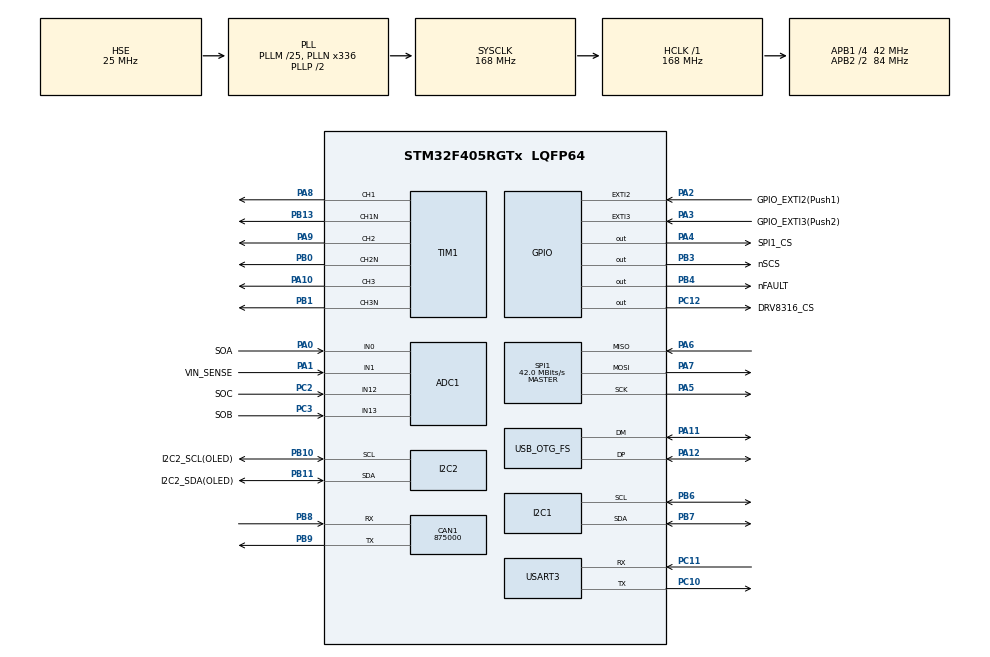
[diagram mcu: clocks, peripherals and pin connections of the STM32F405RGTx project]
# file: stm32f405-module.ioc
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ADC1.Channel-1\#ChannelRegularConversion=ADC_CHANNEL_0
ADC1.NbrOfConversionFlag=1
ADC1.Rank-1\#ChannelRegularConversion=1
ADC1.SamplingTime-1\#ChannelRegularConversion=ADC_SAMPLETIME_3CYCLES
ADC1.master=1
CAN1.BS1=CAN_BS1_1TQ
CAN1.BS2=CAN_BS2_1TQ
CAN1.CalculateBaudRate=875000
CAN1.CalculateTimeBit=1142
CAN1.CalculateTimeQuantum=380.95238095238096
Mcu.Family=STM32F4
Mcu.Name=STM32F405RGTx
Mcu.Package=LQFP64
NVIC.OTG_FS_IRQn=true\:0\:0\:false\:false\:true\:false\:true\:true
NVIC.PriorityGroup=NVIC_PRIORITYGROUP_4
PA0-WKUP.GPIO_Label=SOA
PA0-WKUP.Signal=ADCx_IN0
PA1.GPIO_Label=VIN_SENSE
PA1.Signal=ADCx_IN1
PA10.Signal=S_TIM1_CH3
PA11.Mode=Device_Only
PA11.Signal=USB_OTG_FS_DM
PA12.Mode=Device_Only
PA12.Signal=USB_OTG_FS_DP
PA13.Mode=Serial_Wire
PA13.Signal=SYS_JTMS-SWDIO
PA14.Mode=Serial_Wire
PA14.Signal=SYS_JTCK-SWCLK
PA2.GPIO_Label=GPIO_EXTI2(Push1)
PA2.Signal=GPXTI2
PA3.GPIO_Label=GPIO_EXTI3(Push2)
PA3.Signal=GPXTI3
PA4.GPIO_Label=SPI1_CS
PA4.Signal=GPIO_Output
PA5.Mode=Full_Duplex_Master
PA5.Signal=SPI1_SCK
PA6.Mode=Full_Duplex_Master
PA6.Signal=SPI1_MISO
PA7.Mode=Full_Duplex_Master
PA7.Signal=SPI1_MOSI
PA8.Signal=S_TIM1_CH1
PA9.Signal=S_TIM1_CH2
PB0.Mode=PWM Generation2 CH2 CH2N
PB0.Signal=TIM1_CH2N
PB1.Mode=PWM Generation3 CH3 CH3N
PB1.Signal=TIM1_CH3N
PB10.GPIO_Label=I2C2_SCL(OLED)
PB10.Mode=I2C
PB10.Signal=I2C2_SCL
PB11.GPIO_Label=I2C2_SDA(OLED)
PB11.Mode=I2C
PB11.Signal=I2C2_SDA
PB13.Mode=PWM Generation1 CH1 CH1N
PB13.Signal=TIM1_CH1N
PB3.GPIO_Label=nSCS
PB3.Signal=GPIO_Output
PB4.GPIO_Label=nFAULT
PB4.Signal=GPIO_Output
PB6.Mode=I2C
PB6.Signal=I2C1_SCL
PB7.Mode=I2C
PB7.Signal=I2C1_SDA
PB8.Mode=CAN_Activate
PB8.Signal=CAN1_RX
PB9.Mode=CAN_Activate
PB9.Signal=CAN1_TX
PC10.Mode=Asynchronous
PC10.Signal=USART3_TX
PC11.Mode=Asynchronous
PC11.Signal=USART3_RX
PC12.GPIO_Label=DRV8316_CS
PC12.Signal=GPIO_Output
PC2.GPIO_Label=SOC
PC2.Signal=ADCx_IN12
PC3.GPIO_Label=SOB
PC3.Signal=ADCx_IN13
PH0-OSC_IN.Mode=HSE-External-Oscillator
PH0-OSC_IN.Signal=RCC_OSC_IN
PH1-OSC_OUT.Mode=HSE-External-Oscillator
PH1-OSC_OUT.Signal=RCC_OSC_OUT
ProjectManager.HeapSize=0x200
ProjectManager.StackSize=0x400
ProjectManager.TargetToolchain=CMake
RCC.48MHZClocksFreq_Value=48000000
RCC.AHBFreq_Value=168000000
RCC.APB1CLKDivider=RCC_HCLK_DIV4
RCC.APB1Freq_Value=42000000
RCC.APB1TimFreq_Value=84000000
RCC.APB2CLKDivider=RCC_HCLK_DIV2
RCC.APB2Freq_Value=84000000
RCC.APB2TimFreq_Value=168000000
RCC.CortexFreq_Value=168000000
RCC.HCLKFreq_Value=168000000
RCC.HSE_VALUE=25000000
RCC.HSI_VALUE=16000000
RCC.LSE_VALUE=32768
RCC.PLLM=25
RCC.PLLN=336
RCC.PLLQ=7
RCC.SYSCLKFreq_VALUE=168000000
RCC.SYSCLKSource=RCC_SYSCLKSOURCE_PLLCLK
RCC.VCOOutputFreq_Value=336000000
SH.ADCx_IN0.0=ADC1_IN0,IN0
SH.ADCx_IN1.0=ADC1_IN1,IN1
SH.ADCx_IN12.0=ADC1_IN12,IN12
SH.ADCx_IN13.0=ADC1_IN13,IN13
SH.S_TIM1_CH1.0=TIM1_CH1,PWM Generation1 CH1 CH1N
SH.S_TIM1_CH2.0=TIM1_CH2,PWM Generation2 CH2 CH2N
SH.S_TIM1_CH3.0=TIM1_CH3,PWM Generation3 CH3 CH3N
SPI1.CalculateBaudRate=42.0 MBits/s
SPI1.Direction=SPI_DIRECTION_2LINES
SPI1.Mode=SPI_MODE_MASTER
SPI1.VirtualType=VM_MASTER
TIM1.Channel-PWM\ Generation1\ CH1\ CH1N=TIM_CHANNEL_1
TIM1.Channel-PWM\ Generation2\ CH2\ CH2N=TIM_CHANNEL_2
TIM1.Channel-PWM\ Generation3\ CH3\ CH3N=TIM_CHANNEL_3
USART3.VirtualMode=VM_ASYNC
USB_DEVICE.APP_RX_DATA_SIZE-CDC_FS=512
USB_DEVICE.APP_TX_DATA_SIZE-CDC_FS=512
USB_DEVICE.CLASS_NAME_FS=CDC
USB_DEVICE.VirtualMode-CDC_FS=Cdc
USB_DEVICE.VirtualModeFS=Cdc_FS
USB_OTG_FS.VirtualMode=Device_Only
VP_USB_DEVICE_VS_USB_DEVICE_CDC_FS.Mode=CDC_FS
board=custom

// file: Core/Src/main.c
/* USER CODE BEGIN Header */
/**
  ******************************************************************************
  * @file           : main.c
  * @brief          : Main program body
  ******************************************************************************
  * @attention
  *
  * Copyright (c) 2026 STMicroelectronics.
  * All rights reserved.
  *
  * This software is licensed under terms that can be found in the LICENSE file
  * in the root directory of this software component.
  * If no LICENSE file comes with this software, it is provided AS-IS.
  *
  ******************************************************************************
  */
/* USER CODE END Header */
#include "main.h"
#include "usb_device.h"

/* USER CODE BEGIN Includes */
#include "usbd_cdc_if.h"
#include "ssd1306.h"
/* USER CODE END Includes */

ADC_HandleTypeDef hadc1;

CAN_HandleTypeDef hcan1;

I2C_HandleTypeDef hi2c1;
I2C_HandleTypeDef hi2c2;

SPI_HandleTypeDef hspi1;

TIM_HandleTypeDef htim1;

UART_HandleTypeDef huart3;

void SystemClock_Config(void);
static void MX_GPIO_Init(void);
static void MX_CAN1_Init(void);
static void MX_I2C1_Init(void);
static void MX_SPI1_Init(void);
static void MX_USART3_UART_Init(void);
static void MX_I2C2_Init(void);
static void MX_TIM1_Init(void);
static void MX_ADC1_Init(void);

/* USER CODE BEGIN 0 */
/*
 * Workaround for STM32F4 errata ES0182 "I2C analog filter may provide wrong value,
 * locking BUSY flag and preventing master mode entry". Manually toggles SCL/SDA as
 * GPIO, then resets the peripheral and re-initialises it.
 * Returns 0 on success, or the step number that failed (line did not follow).
 */
static int I2C_BusRecover(I2C_HandleTypeDef *hi2c, GPIO_TypeDef *port, uint16_t scl, uint16_t sda)
{
  GPIO_InitTypeDef gpio = {0};

  __HAL_I2C_DISABLE(hi2c);

  /* Take the pins over as open-drain GPIO, released high */
  HAL_GPIO_WritePin(port, scl | sda, GPIO_PIN_SET);
  gpio.Pin = scl | sda;
  gpio.Mode = GPIO_MODE_OUTPUT_OD;
  gpio.Pull = GPIO_NOPULL;
  gpio.Speed = GPIO_SPEED_FREQ_VERY_HIGH;
  HAL_GPIO_Init(port, &gpio);
  HAL_Delay(1);
  if (HAL_GPIO_ReadPin(port, scl) != GPIO_PIN_SET || HAL_GPIO_ReadPin(port, sda) != GPIO_PIN_SET)
    return 1; /* something external is holding a line low */

  /* Clock out up to 9 pulses in case a slave is stuck mid-byte holding SDA */
  for (int i = 0; i < 9; i++)
  {
    HAL_GPIO_WritePin(port, scl, GPIO_PIN_RESET);
    HAL_Delay(1);
    HAL_GPIO_WritePin(port, scl, GPIO_PIN_SET);
    HAL_Delay(1);
  }

  /* Generate a STOP by hand: SDA low, SCL low, SCL high, SDA high */
  HAL_GPIO_WritePin(port, sda, GPIO_PIN_RESET);
  HAL_Delay(1);
  if (HAL_GPIO_ReadPin(port, sda) != GPIO_PIN_RESET) return 2;
  HAL_GPIO_WritePin(port, scl, GPIO_PIN_RESET);
  HAL_Delay(1);
  if (HAL_GPIO_ReadPin(port, scl) != GPIO_PIN_RESET) return 3;
  HAL_GPIO_WritePin(port, scl, GPIO_PIN_SET);
  HAL_Delay(1);
  if (HAL_GPIO_ReadPin(port, scl) != GPIO_PIN_SET) return 4;
  HAL_GPIO_WritePin(port, sda, GPIO_PIN_SET);
  HAL_Delay(1);
  if (HAL_GPIO_ReadPin(port, sda) != GPIO_PIN_SET) return 5;

  /* Hand the pins back to the I2C peripheral; HAL_I2C_Init does the SWRST pulse */
  HAL_I2C_DeInit(hi2c);
  if (HAL_I2C_Init(hi2c) != HAL_OK) return 6;
  return 0;
}
/* USER CODE END 0 */

int main(void)
{

  /* MCU Configuration--------------------------------------------------------*/

  /* Reset of all peripherals, Initializes the Flash interface and the Systick. */
  HAL_Init();

  /* Configure the system clock */
  SystemClock_Config();

  /* Initialize all configured peripherals */
  MX_GPIO_Init();
  MX_CAN1_Init();
  MX_I2C1_Init();
  MX_SPI1_Init();
  MX_USART3_UART_Init();
  MX_I2C2_Init();
  MX_TIM1_Init();
  MX_ADC1_Init();
  MX_USB_DEVICE_Init();
  /* USER CODE BEGIN 2 */
  int rec = I2C_BusRecover(&hi2c2, GPIOB, I2C2_SCL_Pin, I2C2_SDA_Pin);
  HAL_StatusTypeDef st = HAL_I2C_IsDeviceReady(&hi2c2, 0x3C << 1, 3, 100);
  (void)rec;
  if (st == HAL_OK)
  {
    ssd1306_Init();
    ssd1306_Fill(White);
    ssd1306_UpdateScreen();
  }
  /* USER CODE END 2 */

  /* Infinite loop */
  /* USER CODE BEGIN WHILE */
  while (1)
  {
    CDC_Transmit_FS((uint8_t *)"Hello World!\n", 13);
    HAL_Delay(1000);
    /* USER CODE END WHILE */

  }
}

void SystemClock_Config(void)
{
  RCC_OscInitTypeDef RCC_OscInitStruct = {0};
  RCC_ClkInitTypeDef RCC_ClkInitStruct = {0};

  /** Configure the main internal regulator output voltage
  */
  __HAL_RCC_PWR_CLK_ENABLE();
  __HAL_PWR_VOLTAGESCALING_CONFIG(PWR_REGULATOR_VOLTAGE_SCALE1);

  /** Initializes the RCC Oscillators according to the specified parameters
  * in the RCC_OscInitTypeDef structure.
  */
  RCC_OscInitStruct.OscillatorType = RCC_OSCILLATORTYPE_HSE;
  RCC_OscInitStruct.HSEState = RCC_HSE_ON;
  RCC_OscInitStruct.PLL.PLLState = RCC_PLL_ON;
  RCC_OscInitStruct.PLL.PLLSource = RCC_PLLSOURCE_HSE;
  RCC_OscInitStruct.PLL.PLLM = 25;
  RCC_OscInitStruct.PLL.PLLN = 336;
  RCC_OscInitStruct.PLL.PLLP = RCC_PLLP_DIV2;
  RCC_OscInitStruct.PLL.PLLQ = 7;
  if (HAL_RCC_OscConfig(&RCC_OscInitStruct) != HAL_OK)
  {
    Error_Handler();
  }

  /** Initializes the CPU, AHB and APB buses clocks
  */
  RCC_ClkInitStruct.ClockType = RCC_CLOCKTYPE_HCLK|RCC_CLOCKTYPE_SYSCLK
                              |RCC_CLOCKTYPE_PCLK1|RCC_CLOCKTYPE_PCLK2;
  RCC_ClkInitStruct.SYSCLKSource = RCC_SYSCLKSOURCE_PLLCLK;
  RCC_ClkInitStruct.AHBCLKDivider = RCC_SYSCLK_DIV1;
  RCC_ClkInitStruct.APB1CLKDivider = RCC_HCLK_DIV4;
  RCC_ClkInitStruct.APB2CLKDivider = RCC_HCLK_DIV2;

  if (HAL_RCC_ClockConfig(&RCC_ClkInitStruct, FLASH_LATENCY_5) != HAL_OK)
  {
    Error_Handler();
  }
}

static void MX_ADC1_Init(void)
{

  ADC_ChannelConfTypeDef sConfig = {0};

  /** Configure the global features of the ADC (Clock, Resolution, Data Alignment and number of conversion)
  */
  hadc1.Instance = ADC1;
  hadc1.Init.ClockPrescaler = ADC_CLOCK_SYNC_PCLK_DIV4;
  hadc1.Init.Resolution = ADC_RESOLUTION_12B;
  hadc1.Init.ScanConvMode = DISABLE;
  hadc1.Init.ContinuousConvMode = DISABLE;
  hadc1.Init.DiscontinuousConvMode = DISABLE;
  hadc1.Init.ExternalTrigConvEdge = ADC_EXTERNALTRIGCONVEDGE_NONE;
  hadc1.Init.ExternalTrigConv = ADC_SOFTWARE_START;
  hadc1.Init.DataAlign = ADC_DATAALIGN_RIGHT;
  hadc1.Init.NbrOfConversion = 1;
  hadc1.Init.DMAContinuousRequests = DISABLE;
  hadc1.Init.EOCSelection = ADC_EOC_SINGLE_CONV;
  if (HAL_ADC_Init(&hadc1) != HAL_OK)
  {
    Error_Handler();
  }

  /** Configure for the selected ADC regular channel its corresponding rank in the sequencer and its sample time.
  */
  sConfig.Channel = ADC_CHANNEL_0;
  sConfig.Rank = 1;
  sConfig.SamplingTime = ADC_SAMPLETIME_3CYCLES;
  if (HAL_ADC_ConfigChannel(&hadc1, &sConfig) != HAL_OK)
  {
    Error_Handler();
  }

}

static void MX_CAN1_Init(void)
{

  hcan1.Instance = CAN1;
  hcan1.Init.Prescaler = 16;
  hcan1.Init.Mode = CAN_MODE_NORMAL;
  hcan1.Init.SyncJumpWidth = CAN_SJW_1TQ;
  hcan1.Init.TimeSeg1 = CAN_BS1_1TQ;
  hcan1.Init.TimeSeg2 = CAN_BS2_1TQ;
  hcan1.Init.TimeTriggeredMode = DISABLE;
  hcan1.Init.AutoBusOff = DISABLE;
  hcan1.Init.AutoWakeUp = DISABLE;
  hcan1.Init.AutoRetransmission = DISABLE;
  hcan1.Init.ReceiveFifoLocked = DISABLE;
  hcan1.Init.TransmitFifoPriority = DISABLE;
  if (HAL_CAN_Init(&hcan1) != HAL_OK)
  {
    Error_Handler();
  }

}

static void MX_I2C1_Init(void)
{

  hi2c1.Instance = I2C1;
  hi2c1.Init.ClockSpeed = 100000;
  hi2c1.Init.DutyCycle = I2C_DUTYCYCLE_2;
  hi2c1.Init.OwnAddress1 = 0;
  hi2c1.Init.AddressingMode = I2C_ADDRESSINGMODE_7BIT;
  hi2c1.Init.DualAddressMode = I2C_DUALADDRESS_DISABLE;
  hi2c1.Init.OwnAddress2 = 0;
  hi2c1.Init.GeneralCallMode = I2C_GENERALCALL_DISABLE;
  hi2c1.Init.NoStretchMode = I2C_NOSTRETCH_DISABLE;
  if (HAL_I2C_Init(&hi2c1) != HAL_OK)
  {
    Error_Handler();
  }

}

static void MX_I2C2_Init(void)
{

  hi2c2.Instance = I2C2;
  hi2c2.Init.ClockSpeed = 100000;
  hi2c2.Init.DutyCycle = I2C_DUTYCYCLE_2;
  hi2c2.Init.OwnAddress1 = 0;
  hi2c2.Init.AddressingMode = I2C_ADDRESSINGMODE_7BIT;
  hi2c2.Init.DualAddressMode = I2C_DUALADDRESS_DISABLE;
  hi2c2.Init.OwnAddress2 = 0;
  hi2c2.Init.GeneralCallMode = I2C_GENERALCALL_DISABLE;
  hi2c2.Init.NoStretchMode = I2C_NOSTRETCH_DISABLE;
  if (HAL_I2C_Init(&hi2c2) != HAL_OK)
  {
    Error_Handler();
  }

}

static void MX_SPI1_Init(void)
{

  /* SPI1 parameter configuration*/
  hspi1.Instance = SPI1;
  hspi1.Init.Mode = SPI_MODE_MASTER;
  hspi1.Init.Direction = SPI_DIRECTION_2LINES;
  hspi1.Init.DataSize = SPI_DATASIZE_8BIT;
  hspi1.Init.CLKPolarity = SPI_POLARITY_LOW;
  hspi1.Init.CLKPhase = SPI_PHASE_1EDGE;
  hspi1.Init.NSS = SPI_NSS_SOFT;
  hspi1.Init.BaudRatePrescaler = SPI_BAUDRATEPRESCALER_2;
  hspi1.Init.FirstBit = SPI_FIRSTBIT_MSB;
  hspi1.Init.TIMode = SPI_TIMODE_DISABLE;
  hspi1.Init.CRCCalculation = SPI_CRCCALCULATION_DISABLE;
  hspi1.Init.CRCPolynomial = 10;
  if (HAL_SPI_Init(&hspi1) != HAL_OK)
  {
    Error_Handler();
  }

}

static void MX_TIM1_Init(void)
{

  TIM_MasterConfigTypeDef sMasterConfig = {0};
  TIM_OC_InitTypeDef sConfigOC = {0};
  TIM_BreakDeadTimeConfigTypeDef sBreakDeadTimeConfig = {0};

  htim1.Instance = TIM1;
  htim1.Init.Prescaler = 0;
  htim1.Init.CounterMode = TIM_COUNTERMODE_UP;
  htim1.Init.Period = 65535;
  htim1.Init.ClockDivision = TIM_CLOCKDIVISION_DIV1;
  htim1.Init.RepetitionCounter = 0;
  htim1.Init.AutoReloadPreload = TIM_AUTORELOAD_PRELOAD_DISABLE;
  if (HAL_TIM_PWM_Init(&htim1) != HAL_OK)
  {
    Error_Handler();
  }
  sMasterConfig.MasterOutputTrigger = TIM_TRGO_RESET;
  sMasterConfig.MasterSlaveMode = TIM_MASTERSLAVEMODE_DISABLE;
  if (HAL_TIMEx_MasterConfigSynchronization(&htim1, &sMasterConfig) != HAL_OK)
  {
    Error_Handler();
  }
  sConfigOC.OCMode = TIM_OCMODE_PWM1;
  sConfigOC.Pulse = 0;
  sConfigOC.OCPolarity = TIM_OCPOLARITY_HIGH;
  sConfigOC.OCNPolarity = TIM_OCNPOLARITY_HIGH;
  sConfigOC.OCFastMode = TIM_OCFAST_DISABLE;
  sConfigOC.OCIdleState = TIM_OCIDLESTATE_RESET;
  sConfigOC.OCNIdleState = TIM_OCNIDLESTATE_RESET;
  if (HAL_TIM_PWM_ConfigChannel(&htim1, &sConfigOC, TIM_CHANNEL_1) != HAL_OK)
  {
    Error_Handler();
  }
  if (HAL_TIM_PWM_ConfigChannel(&htim1, &sConfigOC, TIM_CHANNEL_2) != HAL_OK)
  {
    Error_Handler();
  }
  if (HAL_TIM_PWM_ConfigChannel(&htim1, &sConfigOC, TIM_CHANNEL_3) != HAL_OK)
  {
    Error_Handler();
  }
  sBreakDeadTimeConfig.OffStateRunMode = TIM_OSSR_DISABLE;
  sBreakDeadTimeConfig.OffStateIDLEMode = TIM_OSSI_DISABLE;
  sBreakDeadTimeConfig.LockLevel = TIM_LOCKLEVEL_OFF;
  sBreakDeadTimeConfig.DeadTime = 0;
  sBreakDeadTimeConfig.BreakState = TIM_BREAK_DISABLE;
  sBreakDeadTimeConfig.BreakPolarity = TIM_BREAKPOLARITY_HIGH;
  sBreakDeadTimeConfig.AutomaticOutput = TIM_AUTOMATICOUTPUT_DISABLE;
  if (HAL_TIMEx_ConfigBreakDeadTime(&htim1, &sBreakDeadTimeConfig) != HAL_OK)
  {
    Error_Handler();
  }
  HAL_TIM_MspPostInit(&htim1);

}

static void MX_USART3_UART_Init(void)
{

  huart3.Instance = USART3;
  huart3.Init.BaudRate = 115200;
  huart3.Init.WordLength = UART_WORDLENGTH_8B;
  huart3.Init.StopBits = UART_STOPBITS_1;
  huart3.Init.Parity = UART_PARITY_NONE;
  huart3.Init.Mode = UART_MODE_TX_RX;
  huart3.Init.HwFlowCtl = UART_HWCONTROL_NONE;
  huart3.Init.OverSampling = UART_OVERSAMPLING_16;
  if (HAL_UART_Init(&huart3) != HAL_OK)
  {
    Error_Handler();
  }

}

static void MX_GPIO_Init(void)
{
  GPIO_InitTypeDef GPIO_InitStruct = {0};

  /* GPIO Ports Clock Enable */
  __HAL_RCC_GPIOH_CLK_ENABLE();
  __HAL_RCC_GPIOC_CLK_ENABLE();
  __HAL_RCC_GPIOA_CLK_ENABLE();
  __HAL_RCC_GPIOB_CLK_ENABLE();

  /*Configure GPIO pin Output Level */
  HAL_GPIO_WritePin(SPI1_CS_GPIO_Port, SPI1_CS_Pin, GPIO_PIN_RESET);

  /*Configure GPIO pin Output Level */
  HAL_GPIO_WritePin(GPIOB, nSCS_Pin|DRV_OFF_Pin, GPIO_PIN_RESET);

  /*Configure GPIO pins : GPIO_EXTI2_Pin GPIO_EXTI3_Pin */
  GPIO_InitStruct.Pin = GPIO_EXTI2_Pin|GPIO_EXTI3_Pin;
  GPIO_InitStruct.Mode = GPIO_MODE_IT_RISING;
  GPIO_InitStruct.Pull = GPIO_NOPULL;
  HAL_GPIO_Init(GPIOA, &GPIO_InitStruct);

  /*Configure GPIO pin : SPI1_CS_Pin */
  GPIO_InitStruct.Pin = SPI1_CS_Pin;
  GPIO_InitStruct.Mode = GPIO_MODE_OUTPUT_PP;
  GPIO_InitStruct.Pull = GPIO_NOPULL;
  GPIO_InitStruct.Speed = GPIO_SPEED_FREQ_LOW;
  HAL_GPIO_Init(SPI1_CS_GPIO_Port, &GPIO_InitStruct);

  /*Configure GPIO pins : nSCS_Pin DRV_OFF_Pin */
  GPIO_InitStruct.Pin = nSCS_Pin|DRV_OFF_Pin;
  GPIO_InitStruct.Mode = GPIO_MODE_OUTPUT_PP;
  GPIO_InitStruct.Pull = GPIO_NOPULL;
  GPIO_InitStruct.Speed = GPIO_SPEED_FREQ_LOW;
  HAL_GPIO_Init(GPIOB, &GPIO_InitStruct);

}

void Error_Handler(void)
{
  __disable_irq();
  while (1)
  {
  }
}
